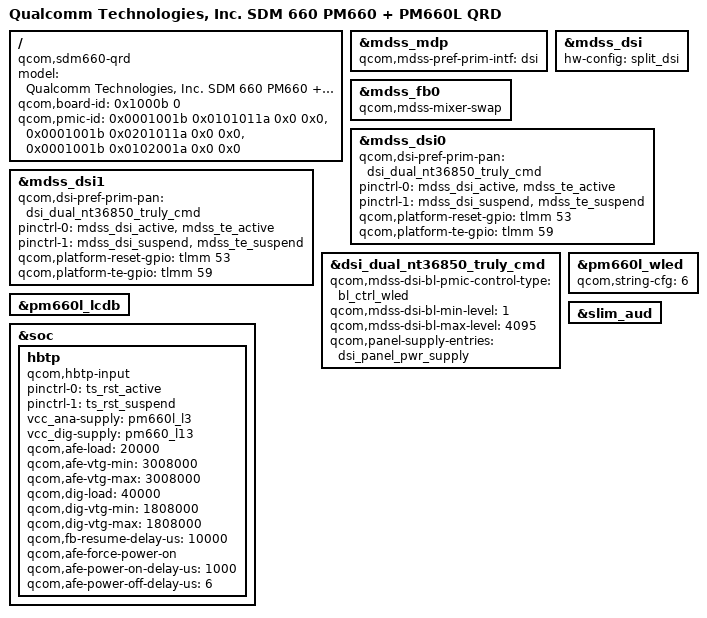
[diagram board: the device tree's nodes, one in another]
/* Copyright (c) 2016-2017, 2020, The Linux Foundation. All rights reserved.
 *
 * This program is free software; you can redistribute it and/or modify
 * it under the terms of the GNU General Public License version 2 and
 * only version 2 as published by the Free Software Foundation.
 *
 * This program is distributed in the hope that it will be useful,
 * but WITHOUT ANY WARRANTY; without even the implied warranty of
 * MERCHANTABILITY or FITNESS FOR A PARTICULAR PURPOSE.  See the
 * GNU General Public License for more details.
 */


/dts-v1/;

#include "sdm660.dtsi"
#include "sdm660-qrd.dtsi"

/ {
	model = "Qualcomm Technologies, Inc. SDM 660 PM660 + PM660L QRD";
	compatible = "qcom,sdm660-qrd", "qcom,sdm660", "qcom,qrd";
	qcom,board-id = <0x1000b 0>;
	qcom,pmic-id = <0x0001001b 0x0101011a 0x0 0x0>,
			<0x0001001b 0x0201011a 0x0 0x0>,
			<0x0001001b 0x0102001a 0x0 0x0>;
};

&mdss_mdp {
	qcom,mdss-pref-prim-intf = "dsi";
};

&mdss_fb0 {
	qcom,mdss-mixer-swap;
};

&mdss_dsi {
	hw-config = "split_dsi";
};

&mdss_dsi0 {
	qcom,dsi-pref-prim-pan = <&dsi_dual_nt36850_truly_cmd>;
	pinctrl-names = "mdss_default", "mdss_sleep";
	pinctrl-0 = <&mdss_dsi_active &mdss_te_active>;
	pinctrl-1 = <&mdss_dsi_suspend &mdss_te_suspend>;
	qcom,platform-reset-gpio = <&tlmm 53 0>;
	qcom,platform-te-gpio = <&tlmm 59 0>;
};

&mdss_dsi1 {
	qcom,dsi-pref-prim-pan = <&dsi_dual_nt36850_truly_cmd>;
	pinctrl-names = "mdss_default", "mdss_sleep";
	pinctrl-0 = <&mdss_dsi_active &mdss_te_active>;
	pinctrl-1 = <&mdss_dsi_suspend &mdss_te_suspend>;
	qcom,platform-reset-gpio = <&tlmm 53 0>;
	qcom,platform-te-gpio = <&tlmm 59 0>;
};

&dsi_dual_nt36850_truly_cmd {
	qcom,mdss-dsi-bl-pmic-control-type = "bl_ctrl_wled";
	qcom,mdss-dsi-bl-min-level = <1>;
	qcom,mdss-dsi-bl-max-level = <4095>;
	qcom,panel-supply-entries = <&dsi_panel_pwr_supply>;
};

&pm660l_wled {
	qcom,string-cfg= <6>;
	status = "ok";
};

&pm660l_lcdb {
	status = "ok";
};

&soc {
	hbtp {
		compatible = "qcom,hbtp-input";
		pinctrl-names = "pmx_ts_active", "pmx_ts_suspend";
		pinctrl-0 = <&ts_rst_active>;
		pinctrl-1 = <&ts_rst_suspend>;
		vcc_ana-supply = <&pm660l_l3>;
		vcc_dig-supply = <&pm660_l13>;
		qcom,afe-load = <20000>;
		qcom,afe-vtg-min = <3008000>;
		qcom,afe-vtg-max = <3008000>;
		qcom,dig-load = <40000>;
		qcom,dig-vtg-min = <1808000>;
		qcom,dig-vtg-max = <1808000>;
		qcom,fb-resume-delay-us = <10000>;
		qcom,afe-force-power-on;
		qcom,afe-power-on-delay-us = <1000>;
		qcom,afe-power-off-delay-us = <6>;
	};
};

&slim_aud {
	/delete-node/wcd934x_cdc;
};

&soc {
	/delete-node/sound-tavil;
};

